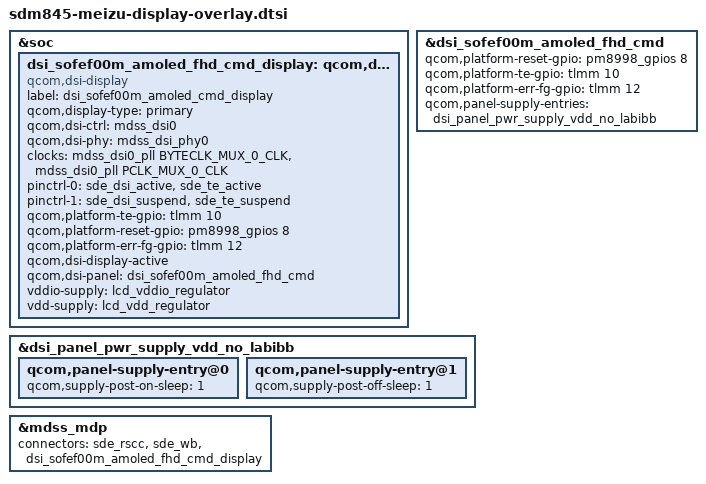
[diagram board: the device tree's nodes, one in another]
/* Copyright (c) 2022, MeizuCustoms enthusiasts
 *
 * This program is free software; you can redistribute it and/or modify
 * it under the terms of the GNU General Public License version 2 and
 * only version 2 as published by the Free Software Foundation.
 *
 * This program is distributed in the hope that it will be useful,
 * but WITHOUT ANY WARRANTY; without even the implied warranty of
 * MERCHANTABILITY or FITNESS FOR A PARTICULAR PURPOSE.  See the
 * GNU General Public License for more details.
 */

#include "dsi-panel-sofef00m-amoled-fhd-cmd.dtsi"

&soc {
	dsi_sofef00m_amoled_fhd_cmd_display: qcom,dsi-display@17 {
		compatible = "qcom,dsi-display";
		label = "dsi_sofef00m_amoled_cmd_display";
		qcom,display-type = "primary";

		qcom,dsi-ctrl = <&mdss_dsi0>;
		qcom,dsi-phy = <&mdss_dsi_phy0>;
		clocks = <&mdss_dsi0_pll BYTECLK_MUX_0_CLK>,
			<&mdss_dsi0_pll PCLK_MUX_0_CLK>;
		clock-names = "src_byte_clk", "src_pixel_clk";

		pinctrl-names = "panel_active", "panel_suspend";
		pinctrl-0 = <&sde_dsi_active &sde_te_active>;
		pinctrl-1 = <&sde_dsi_suspend &sde_te_suspend>;
		qcom,platform-te-gpio = <&tlmm 10 0>;
		qcom,platform-reset-gpio = <&pm8998_gpios 8 0>;
		qcom,platform-err-fg-gpio = <&tlmm 12 0>;

		qcom,dsi-display-active;

		qcom,dsi-panel = <&dsi_sofef00m_amoled_fhd_cmd>;
		vddio-supply = <&lcd_vddio_regulator>;
		vdd-supply = <&lcd_vdd_regulator>;
	};
};

&dsi_sofef00m_amoled_fhd_cmd {
    qcom,platform-reset-gpio = <&pm8998_gpios 8 0>;
    qcom,platform-te-gpio = <&tlmm 10 0>;
    qcom,platform-err-fg-gpio = <&tlmm 12 0>;

    qcom,panel-supply-entries = <&dsi_panel_pwr_supply_vdd_no_labibb>;
};

&dsi_panel_pwr_supply_vdd_no_labibb {
    qcom,panel-supply-entry@0 {
        /delete-property/ qcom,supply-post-off-sleep;
        qcom,supply-post-on-sleep = <1>;
    };

    qcom,panel-supply-entry@1 {
        /delete-property/ qcom,supply-post-on-sleep;
        qcom,supply-post-off-sleep = <1>;
    };
};

&mdss_mdp {
	connectors = <&sde_rscc &sde_wb &dsi_sofef00m_amoled_fhd_cmd_display>;
};
